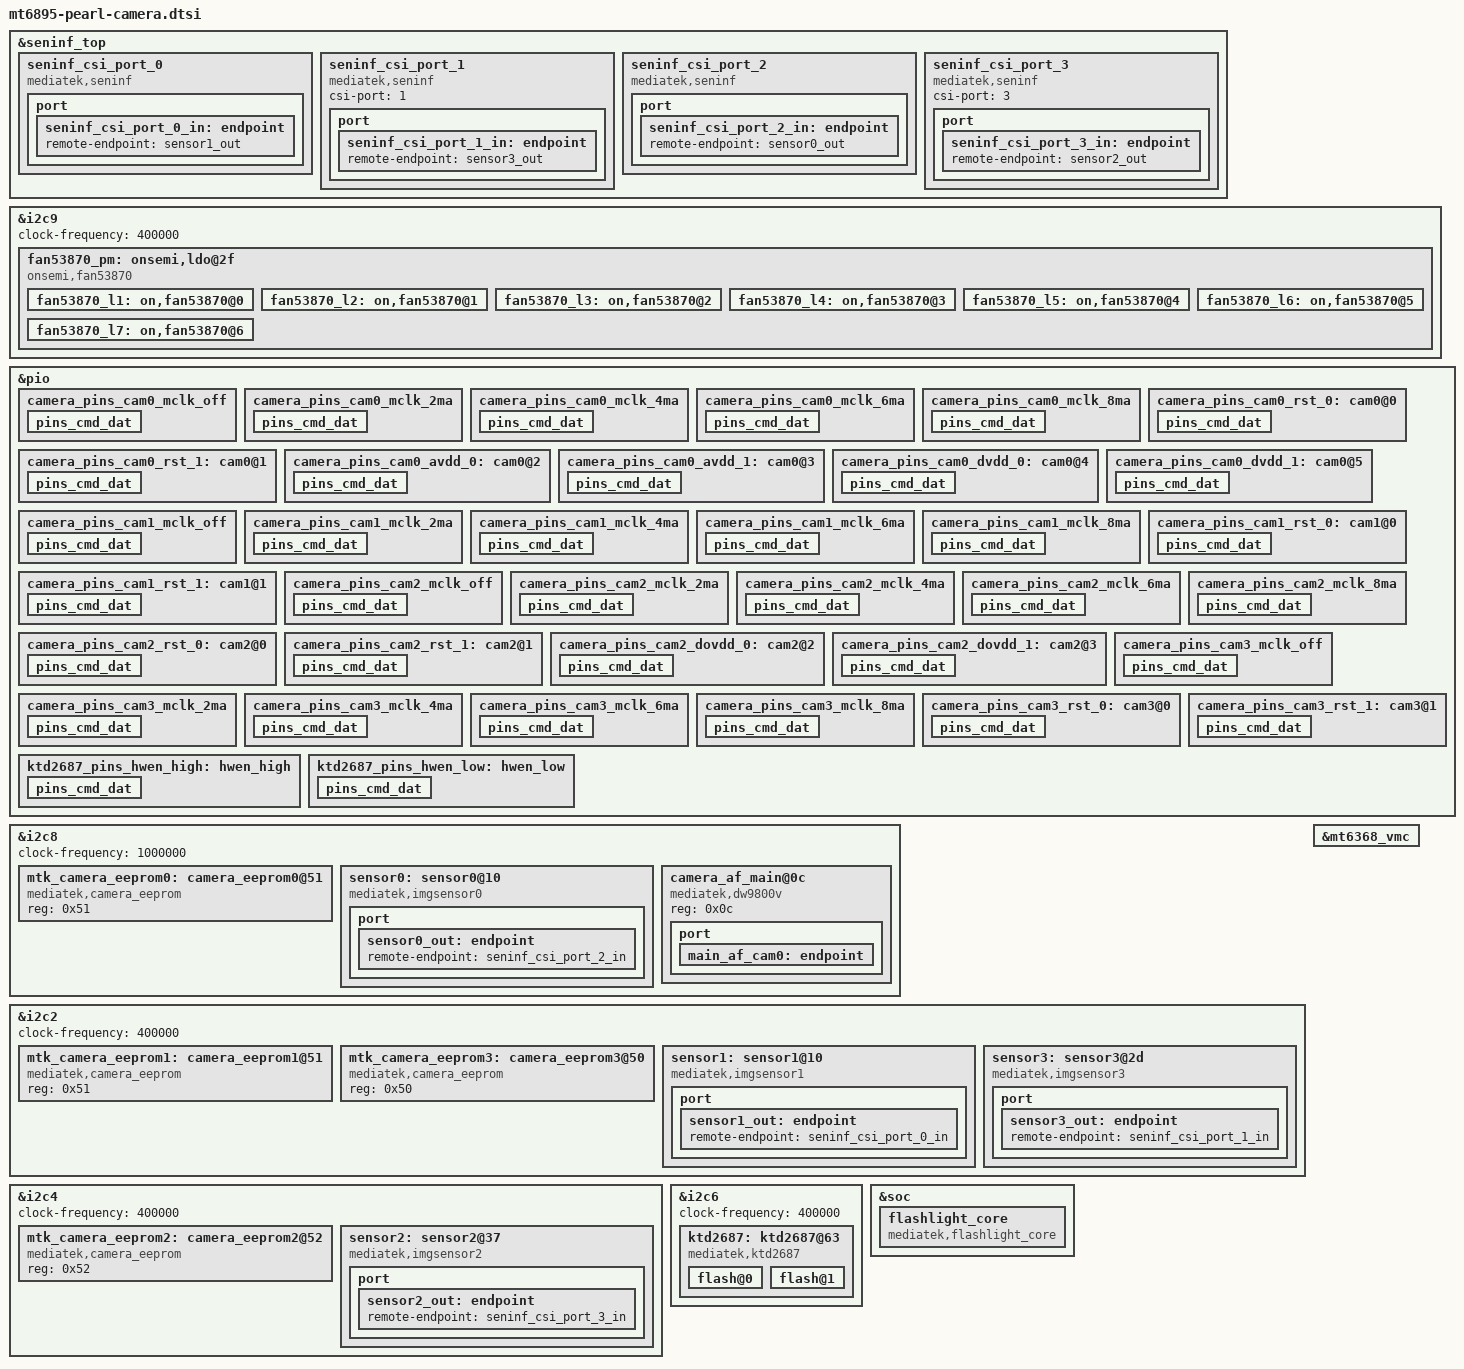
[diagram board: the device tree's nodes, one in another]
// SPDX-License-Identifier: GPL-2.0
/*
 * Copyright (c) 2020 MediaTek Inc.
 *
 * pearl (Redmi Note 12T Pro / MT6895) camera device tree.
 *
 * Every value here was taken from two independent sources and cross-checked
 * against each other:
 *
 *   1. the vendor kernel tree's pearl_mt6895_camera_v4l2.dtsi, and
 *   2. the stock firmware actually flashed on this device -- the dtbo
 *      partition (/dev/disk/by-partlabel/dtbo_a) was dumped, its embedded
 *      DTB extracted and decompiled, and the sensor nodes read out of it.
 *
 * They agree, which also settles the sensor question: pearl is NOT xaga.
 * xaga's main camera is an S5KGW1/S5KHM2; pearl's is an OV64B, and there is
 * no OV64B driver anywhere in the xaga-derived tree -- pearl's four sensor
 * drivers were ported separately from the vendor tree.
 *
 *   sensor0  pearl ov64b_mipi_raw    i2c8 @0x10  CSI port 2  (main, 64MP)
 *   sensor1  pearl ov16a1_mipi_raw   i2c2 @0x10  CSI port 0  (front, 16MP)
 *   sensor2  pearl gc02m1_mipi_raw   i2c4 @0x37  CSI port 3  (macro, 2MP)
 *   sensor3  pearl s5k4h7_mipi_raw   i2c2 @0x2d  CSI port 1  (sub, 8MP)
 *
 * All four are powered by the FAN53870 PMIC on i2c9 @0x35.  The EEPROMs
 * (calibration data) sit at 0x50/0x51/0x52 on the same buses as their
 * sensors, and the main camera additionally switches its own avdd/dvdd
 * through GPIOs (149/159), the macro its dovdd (144).
 */

#include <dt-bindings/clock/mt6895-clk.h>
#include <dt-bindings/gpio/gpio.h>
/* PINMUX_* macros come from mt6895-pinfunc.h, pulled in by mt6895.dtsi. */

/* ------------------------------------------------------------------ */
/* CSI receivers: which physical port each sensor lands on             */
/* ------------------------------------------------------------------ */
&seninf_top {
	seninf_csi_port_0: seninf_csi_port_0 {
		compatible = "mediatek,seninf";
		csi-port = "0";
		seninf_dphy_settle_delay_dt = <7>;
		dphy_settle_delay_dt = <7>;
		settle_delay_ck = <7>;
		hs_trail_parameter = <102>;
		status = "okay";

		port {
			seninf_csi_port_0_in: endpoint {
				remote-endpoint = <&sensor1_out>;
			};
		};
	};

	seninf_csi_port_1: seninf_csi_port_1 {
		compatible = "mediatek,seninf";
		csi-port = "1";
		status = "okay";

		port {
			seninf_csi_port_1_in: endpoint {
				remote-endpoint = <&sensor3_out>;
			};
		};
	};

	seninf_csi_port_2: seninf_csi_port_2 {
		compatible = "mediatek,seninf";
		csi-port = "2";
		seninf_dphy_settle_delay_dt = <7>;
		dphy_settle_delay_dt = <7>;
		settle_delay_ck = <7>;
		hs_trail_parameter = <32>;
		status = "okay";

		port {
			seninf_csi_port_2_in: endpoint {
				remote-endpoint = <&sensor0_out>;
			};
		};
	};

	seninf_csi_port_3: seninf_csi_port_3 {
		compatible = "mediatek,seninf";
		csi-port = "3";
		status = "okay";

		port {
			seninf_csi_port_3_in: endpoint {
				remote-endpoint = <&sensor2_out>;
			};
		};
	};
};

/* ------------------------------------------------------------------ */
/* FAN53870 camera PMIC: all four sensors hang off these rails         */
/* ------------------------------------------------------------------ */
&i2c9 {
	status = "okay";
	#address-cells = <1>;
	#size-cells = <0>;
	clock-frequency = <400000>;

	/*
	 * PEARL: real slave address is 0x2f, not the 0x35 the stock DT names.
	 * Measured with i2cdetect/i2cget on the running kernel:
	 *
	 *     0x35  -> "Error: Read failed"          (nothing there)
	 *     0x2f  -> PID=0x82 RID=0x33 IOUT=0x00 ENABLE=0x58 LDO0=0x58
	 *              0x05..0x09 = 0xa2 x5 (LDO1..LDO5)
	 *
	 * which is exactly the FAN53870 register map the driver defines
	 * (fan53870.c: REG_PID/RID/IOUT/ENABLE/LDO0 at 0x00..0x04).  sc8551
	 * answers on the same bus at 0x66, so the controller is fine -- the
	 * address in the DT was simply wrong, and the probe deferred forever,
	 * which is what all four sensors were waiting on.
	 */
	fan53870_pm: onsemi,ldo@2f {
		compatible = "onsemi,fan53870";
		reg = <0x2f>;
		index = <0>;
		/*
		 * PEARL: the driver's own comment names this rail.  Without
		 * it devm_regulator_get_optional("vin") returns -ENODEV, the
		 * probe runs with the chip unpowered, the PID read fails with
		 * -ENXIO and it defers forever -- which is exactly what the
		 * four camera sensors were waiting on.
		 */
		vin-supply = <&mt6368_vio28>;
		status = "okay";

		fan53870_l1: on,fan53870@0 {
			offset = /bits/ 16 <0x0000>;
			regulator-name = "fan53870-l1";
			regulator-min-microvolt = <528000>;
			regulator-max-microvolt = <1504000>;
			min-dropout-voltage = <225000>;
			init-voltage = <1150000>;
			iout_ua = <650000>;
		};

		fan53870_l2: on,fan53870@1 {
			offset = /bits/ 16 <0x0001>;
			regulator-name = "fan53870-l2";
			regulator-min-microvolt = <528000>;
			regulator-max-microvolt = <1504000>;
			min-dropout-voltage = <225000>;
			init-voltage = <1200000>;
			iout_ua = <650000>;
		};

		fan53870_l3: on,fan53870@2 {
			offset = /bits/ 16 <0x0002>;
			regulator-name = "fan53870-l3";
			regulator-min-microvolt = <1504000>;
			regulator-max-microvolt = <3400000>;
			min-dropout-voltage = <200000>;
			init-voltage = <2900000>;
			iout_ua = <650000>;
		};

		fan53870_l4: on,fan53870@3 {
			offset = /bits/ 16 <0x0003>;
			regulator-name = "fan53870-l4";
			regulator-min-microvolt = <1504000>;
			regulator-max-microvolt = <3400000>;
			min-dropout-voltage = <200000>;
			init-voltage = <2800000>;
			iout_ua = <650000>;
		};

		fan53870_l5: on,fan53870@4 {
			offset = /bits/ 16 <0x0004>;
			regulator-name = "fan53870-l5";
			regulator-min-microvolt = <1504000>;
			regulator-max-microvolt = <3400000>;
			min-dropout-voltage = <300000>;
			init-voltage = <2800000>;
			iout_ua = <650000>;
		};

		fan53870_l6: on,fan53870@5 {
			offset = /bits/ 16 <0x0005>;
			regulator-name = "fan53870-l6";
			regulator-min-microvolt = <1504000>;
			regulator-max-microvolt = <3400000>;
			min-dropout-voltage = <300000>;
			init-voltage = <2800000>;
			iout_ua = <650000>;
		};

		fan53870_l7: on,fan53870@6 {
			offset = /bits/ 16 <0x0006>;
			regulator-name = "fan53870-l7";
			regulator-min-microvolt = <1504000>;
			regulator-max-microvolt = <3400000>;
			min-dropout-voltage = <300000>;
			init-voltage = <2800000>;
			iout_ua = <650000>;
		};
	};
};

/* ------------------------------------------------------------------ */
/* Camera pin control                                                  */
/*                                                                     */
/* MCLK: cam0 = GPIO152 (CMMCLK2), cam1 = GPIO150 (CMMCLK0),           */
/*       cam2 = GPIO151 (CMMCLK1), cam3 = GPIO162 (CMMCLK3)            */
/* RESET: cam0 = 155, cam1 = 153, cam2 = 154, cam3 = 156               */
/* Main camera also gates its own avdd (149) and dvdd (159);           */
/* the macro gates its dovdd (144).                                    */
/* ------------------------------------------------------------------ */
&pio {
	camera_pins_cam0_mclk_off: camera_pins_cam0_mclk_off {
		pins_cmd_dat {
			pinmux = <PINMUX_GPIO152__FUNC_GPIO152>;
			drive-strength = <1>;
		};
	};
	camera_pins_cam0_mclk_2ma: camera_pins_cam0_mclk_2ma {
		pins_cmd_dat {
			pinmux = <PINMUX_GPIO152__FUNC_CMMCLK2>;
			drive-strength = <0>;
		};
	};
	camera_pins_cam0_mclk_4ma: camera_pins_cam0_mclk_4ma {
		pins_cmd_dat {
			pinmux = <PINMUX_GPIO152__FUNC_CMMCLK2>;
			drive-strength = <1>;
		};
	};
	camera_pins_cam0_mclk_6ma: camera_pins_cam0_mclk_6ma {
		pins_cmd_dat {
			pinmux = <PINMUX_GPIO152__FUNC_CMMCLK2>;
			drive-strength = <2>;
		};
	};
	camera_pins_cam0_mclk_8ma: camera_pins_cam0_mclk_8ma {
		pins_cmd_dat {
			pinmux = <PINMUX_GPIO152__FUNC_CMMCLK2>;
			drive-strength = <3>;
		};
	};
	camera_pins_cam0_rst_0: cam0@0 {
		pins_cmd_dat {
			pinmux = <PINMUX_GPIO155__FUNC_GPIO155>;
			slew-rate = <1>;
			output-low;
		};
	};
	camera_pins_cam0_rst_1: cam0@1 {
		pins_cmd_dat {
			pinmux = <PINMUX_GPIO155__FUNC_GPIO155>;
			slew-rate = <1>;
			output-high;
		};
	};
	camera_pins_cam0_avdd_0: cam0@2 {
		pins_cmd_dat {
			pinmux = <PINMUX_GPIO149__FUNC_GPIO149>;
			slew-rate = <1>;
			output-low;
		};
	};
	camera_pins_cam0_avdd_1: cam0@3 {
		pins_cmd_dat {
			pinmux = <PINMUX_GPIO149__FUNC_GPIO149>;
			slew-rate = <1>;
			output-high;
		};
	};
	camera_pins_cam0_dvdd_0: cam0@4 {
		pins_cmd_dat {
			pinmux = <PINMUX_GPIO159__FUNC_GPIO159>;
			slew-rate = <1>;
			output-low;
		};
	};
	camera_pins_cam0_dvdd_1: cam0@5 {
		pins_cmd_dat {
			pinmux = <PINMUX_GPIO159__FUNC_GPIO159>;
			slew-rate = <1>;
			output-high;
		};
	};

	camera_pins_cam1_mclk_off: camera_pins_cam1_mclk_off {
		pins_cmd_dat {
			pinmux = <PINMUX_GPIO150__FUNC_GPIO150>;
			drive-strength = <1>;
		};
	};
	camera_pins_cam1_mclk_2ma: camera_pins_cam1_mclk_2ma {
		pins_cmd_dat {
			pinmux = <PINMUX_GPIO150__FUNC_CMMCLK0>;
			drive-strength = <0>;
		};
	};
	camera_pins_cam1_mclk_4ma: camera_pins_cam1_mclk_4ma {
		pins_cmd_dat {
			pinmux = <PINMUX_GPIO150__FUNC_CMMCLK0>;
			drive-strength = <1>;
		};
	};
	camera_pins_cam1_mclk_6ma: camera_pins_cam1_mclk_6ma {
		pins_cmd_dat {
			pinmux = <PINMUX_GPIO150__FUNC_CMMCLK0>;
			drive-strength = <2>;
		};
	};
	camera_pins_cam1_mclk_8ma: camera_pins_cam1_mclk_8ma {
		pins_cmd_dat {
			pinmux = <PINMUX_GPIO150__FUNC_CMMCLK0>;
			drive-strength = <3>;
		};
	};
	camera_pins_cam1_rst_0: cam1@0 {
		pins_cmd_dat {
			pinmux = <PINMUX_GPIO153__FUNC_GPIO153>;
			slew-rate = <1>;
			output-low;
		};
	};
	camera_pins_cam1_rst_1: cam1@1 {
		pins_cmd_dat {
			pinmux = <PINMUX_GPIO153__FUNC_GPIO153>;
			slew-rate = <1>;
			output-high;
		};
	};

	camera_pins_cam2_mclk_off: camera_pins_cam2_mclk_off {
		pins_cmd_dat {
			pinmux = <PINMUX_GPIO151__FUNC_GPIO151>;
			drive-strength = <1>;
		};
	};
	camera_pins_cam2_mclk_2ma: camera_pins_cam2_mclk_2ma {
		pins_cmd_dat {
			pinmux = <PINMUX_GPIO151__FUNC_CMMCLK1>;
			drive-strength = <0>;
		};
	};
	camera_pins_cam2_mclk_4ma: camera_pins_cam2_mclk_4ma {
		pins_cmd_dat {
			pinmux = <PINMUX_GPIO151__FUNC_CMMCLK1>;
			drive-strength = <1>;
		};
	};
	camera_pins_cam2_mclk_6ma: camera_pins_cam2_mclk_6ma {
		pins_cmd_dat {
			pinmux = <PINMUX_GPIO151__FUNC_CMMCLK1>;
			drive-strength = <2>;
		};
	};
	camera_pins_cam2_mclk_8ma: camera_pins_cam2_mclk_8ma {
		pins_cmd_dat {
			pinmux = <PINMUX_GPIO151__FUNC_CMMCLK1>;
			drive-strength = <3>;
		};
	};
	camera_pins_cam2_rst_0: cam2@0 {
		pins_cmd_dat {
			pinmux = <PINMUX_GPIO154__FUNC_GPIO154>;
			slew-rate = <1>;
			output-low;
		};
	};
	camera_pins_cam2_rst_1: cam2@1 {
		pins_cmd_dat {
			pinmux = <PINMUX_GPIO154__FUNC_GPIO154>;
			slew-rate = <1>;
			output-high;
		};
	};
	camera_pins_cam2_dovdd_0: cam2@2 {
		pins_cmd_dat {
			pinmux = <PINMUX_GPIO144__FUNC_GPIO144>;
			slew-rate = <1>;
			output-low;
		};
	};
	camera_pins_cam2_dovdd_1: cam2@3 {
		pins_cmd_dat {
			pinmux = <PINMUX_GPIO144__FUNC_GPIO144>;
			slew-rate = <1>;
			output-high;
		};
	};

	camera_pins_cam3_mclk_off: camera_pins_cam3_mclk_off {
		pins_cmd_dat {
			pinmux = <PINMUX_GPIO162__FUNC_GPIO162>;
			drive-strength = <1>;
		};
	};
	camera_pins_cam3_mclk_2ma: camera_pins_cam3_mclk_2ma {
		pins_cmd_dat {
			pinmux = <PINMUX_GPIO162__FUNC_CMMCLK3>;
			drive-strength = <0>;
		};
	};
	camera_pins_cam3_mclk_4ma: camera_pins_cam3_mclk_4ma {
		pins_cmd_dat {
			pinmux = <PINMUX_GPIO162__FUNC_CMMCLK3>;
			drive-strength = <1>;
		};
	};
	camera_pins_cam3_mclk_6ma: camera_pins_cam3_mclk_6ma {
		pins_cmd_dat {
			pinmux = <PINMUX_GPIO162__FUNC_CMMCLK3>;
			drive-strength = <2>;
		};
	};
	camera_pins_cam3_mclk_8ma: camera_pins_cam3_mclk_8ma {
		pins_cmd_dat {
			pinmux = <PINMUX_GPIO162__FUNC_CMMCLK3>;
			drive-strength = <3>;
		};
	};
	camera_pins_cam3_rst_0: cam3@0 {
		pins_cmd_dat {
			pinmux = <PINMUX_GPIO156__FUNC_GPIO156>;
			slew-rate = <1>;
			output-low;
		};
	};
	camera_pins_cam3_rst_1: cam3@1 {
		pins_cmd_dat {
			pinmux = <PINMUX_GPIO156__FUNC_GPIO156>;
			slew-rate = <1>;
			output-high;
		};
	};
};

/* ------------------------------------------------------------------ */
/* sensor0: main camera, OV64B 64MP, on i2c8                           */
/* ------------------------------------------------------------------ */
&i2c8 {
	status = "okay";
	#address-cells = <1>;
	#size-cells = <0>;
	clock-frequency = <400000>;

	mtk_camera_eeprom0: camera_eeprom0@51 {
		compatible = "mediatek,camera_eeprom";
		reg = <0x51>;
		status = "okay";
	};

	sensor0: sensor0@10 {
		compatible = "mediatek,imgsensor0";
		reg = <0x10>;
		sensor-names = "pearlov64b_mipi_raw";
		#thermal-sensor-cells = <0>;

		pinctrl-names = "mclk_off",
				"mclk_2mA",
				"mclk_4mA",
				"mclk_6mA",
				"mclk_8mA",
				"rst_low",
				"rst_high",
				"avdd_off",
				"avdd_on",
				"dvdd_off",
				"dvdd_on";
		pinctrl-0 = <&camera_pins_cam0_mclk_off>;
		pinctrl-1 = <&camera_pins_cam0_mclk_2ma>;
		pinctrl-2 = <&camera_pins_cam0_mclk_4ma>;
		pinctrl-3 = <&camera_pins_cam0_mclk_6ma>;
		pinctrl-4 = <&camera_pins_cam0_mclk_8ma>;
		pinctrl-5 = <&camera_pins_cam0_rst_0>;
		pinctrl-6 = <&camera_pins_cam0_rst_1>;
		pinctrl-7 = <&camera_pins_cam0_avdd_0>;
		pinctrl-8 = <&camera_pins_cam0_avdd_1>;
		pinctrl-9 = <&camera_pins_cam0_dvdd_0>;
		pinctrl-10 = <&camera_pins_cam0_dvdd_1>;

		dovdd-supply = <&fan53870_l7>;
		afvdd-supply = <&fan53870_l6>;

		clocks = <&topckgen CLK_TOP_UNIVPLL_192M_D32>,
			<&topckgen CLK_TOP_UNIVPLL_192M_D16>,
			<&topckgen CLK_TOP_F26M_CK_D2>,
			<&topckgen CLK_TOP_UNIVPLL_192M_D10>,
			<&topckgen CLK_TOP_UNIVPLL_192M_D8>,
			<&clk26m>,
			<&topckgen CLK_TOP_UNIVPLL_D6_D8>,
			<&topckgen CLK_TOP_CAMTG_SEL>;
		clock-names = "6", "12", "13", "19.2", "24", "26", "52", "mclk";

		status = "okay";

		port {
			sensor0_out: endpoint {
				remote-endpoint = <&seninf_csi_port_2_in>;
			};
		};
	};
};

/* ------------------------------------------------------------------ */
/* sensor1 (front, OV16A1) and sensor3 (sub, S5K4H7) share i2c2        */
/* ------------------------------------------------------------------ */
&i2c2 {
	status = "okay";
	#address-cells = <1>;
	#size-cells = <0>;
	clock-frequency = <400000>;

	mtk_camera_eeprom1: camera_eeprom1@51 {
		compatible = "mediatek,camera_eeprom";
		reg = <0x51>;
		status = "okay";
	};

	mtk_camera_eeprom3: camera_eeprom3@50 {
		compatible = "mediatek,camera_eeprom";
		reg = <0x50>;
		status = "okay";
	};

	sensor1: sensor1@10 {
		compatible = "mediatek,imgsensor1";
		reg = <0x10>;
		sensor-names = "pearlov16a1_mipi_raw";
		#thermal-sensor-cells = <0>;

		pinctrl-names = "mclk_off",
				"mclk_2mA",
				"mclk_4mA",
				"mclk_6mA",
				"mclk_8mA",
				"rst_low",
				"rst_high";
		pinctrl-0 = <&camera_pins_cam1_mclk_off>;
		pinctrl-1 = <&camera_pins_cam1_mclk_2ma>;
		pinctrl-2 = <&camera_pins_cam1_mclk_4ma>;
		pinctrl-3 = <&camera_pins_cam1_mclk_6ma>;
		pinctrl-4 = <&camera_pins_cam1_mclk_8ma>;
		pinctrl-5 = <&camera_pins_cam1_rst_0>;
		pinctrl-6 = <&camera_pins_cam1_rst_1>;

		dovdd-supply = <&fan53870_l7>;
		avdd-supply = <&fan53870_l3>;
		dvdd-supply = <&fan53870_l1>;

		clocks = <&topckgen CLK_TOP_UNIVPLL_192M_D32>,
			<&topckgen CLK_TOP_UNIVPLL_192M_D16>,
			<&topckgen CLK_TOP_F26M_CK_D2>,
			<&topckgen CLK_TOP_UNIVPLL_192M_D10>,
			<&topckgen CLK_TOP_UNIVPLL_192M_D8>,
			<&clk26m>,
			<&topckgen CLK_TOP_UNIVPLL_D6_D8>,
			<&topckgen CLK_TOP_CAMTG_SEL>;
		clock-names = "6", "12", "13", "19.2", "24", "26", "52", "mclk";

		status = "okay";

		port {
			sensor1_out: endpoint {
				remote-endpoint = <&seninf_csi_port_0_in>;
			};
		};
	};

	sensor3: sensor3@2d {
		compatible = "mediatek,imgsensor3";
		reg = <0x2d>;
		sensor-names = "pearls5k4h7_mipi_raw";
		#thermal-sensor-cells = <0>;

		pinctrl-names = "mclk_off",
				"mclk_2mA",
				"mclk_4mA",
				"mclk_6mA",
				"mclk_8mA",
				"rst_low",
				"rst_high";
		pinctrl-0 = <&camera_pins_cam3_mclk_off>;
		pinctrl-1 = <&camera_pins_cam3_mclk_2ma>;
		pinctrl-2 = <&camera_pins_cam3_mclk_4ma>;
		pinctrl-3 = <&camera_pins_cam3_mclk_6ma>;
		pinctrl-4 = <&camera_pins_cam3_mclk_8ma>;
		pinctrl-5 = <&camera_pins_cam3_rst_0>;
		pinctrl-6 = <&camera_pins_cam3_rst_1>;

		dovdd-supply = <&fan53870_l7>;
		avdd-supply = <&fan53870_l4>;
		dvdd-supply = <&fan53870_l2>;

		clocks = <&topckgen CLK_TOP_UNIVPLL_192M_D32>,
			<&topckgen CLK_TOP_UNIVPLL_192M_D16>,
			<&topckgen CLK_TOP_F26M_CK_D2>,
			<&topckgen CLK_TOP_UNIVPLL_192M_D10>,
			<&topckgen CLK_TOP_UNIVPLL_192M_D8>,
			<&clk26m>,
			<&topckgen CLK_TOP_UNIVPLL_D6_D8>,
			<&topckgen CLK_TOP_CAMTG_SEL>;
		clock-names = "6", "12", "13", "19.2", "24", "26", "52", "mclk";

		status = "okay";

		port {
			sensor3_out: endpoint {
				remote-endpoint = <&seninf_csi_port_1_in>;
			};
		};
	};
};

/* ------------------------------------------------------------------ */
/* sensor2: macro camera, GC02M1 2MP, on i2c4                          */
/* ------------------------------------------------------------------ */
&i2c4 {
	status = "okay";
	#address-cells = <1>;
	#size-cells = <0>;
	clock-frequency = <400000>;

	mtk_camera_eeprom2: camera_eeprom2@52 {
		compatible = "mediatek,camera_eeprom";
		reg = <0x52>;
		status = "okay";
	};

	sensor2: sensor2@37 {
		compatible = "mediatek,imgsensor2";
		reg = <0x37>;
		sensor-names = "pearlgc02m1_mipi_raw";
		#thermal-sensor-cells = <0>;

		pinctrl-names = "mclk_off",
				"mclk_2mA",
				"mclk_4mA",
				"mclk_6mA",
				"mclk_8mA",
				"rst_low",
				"rst_high",
				"dovdd_off",
				"dovdd_on";
		pinctrl-0 = <&camera_pins_cam2_mclk_off>;
		pinctrl-1 = <&camera_pins_cam2_mclk_2ma>;
		pinctrl-2 = <&camera_pins_cam2_mclk_4ma>;
		pinctrl-3 = <&camera_pins_cam2_mclk_6ma>;
		pinctrl-4 = <&camera_pins_cam2_mclk_8ma>;
		pinctrl-5 = <&camera_pins_cam2_rst_0>;
		pinctrl-6 = <&camera_pins_cam2_rst_1>;
		pinctrl-7 = <&camera_pins_cam2_dovdd_0>;
		pinctrl-8 = <&camera_pins_cam2_dovdd_1>;

		avdd-supply = <&fan53870_l5>;

		clocks = <&topckgen CLK_TOP_UNIVPLL_192M_D32>,
			<&topckgen CLK_TOP_UNIVPLL_192M_D16>,
			<&topckgen CLK_TOP_F26M_CK_D2>,
			<&topckgen CLK_TOP_UNIVPLL_192M_D10>,
			<&topckgen CLK_TOP_UNIVPLL_192M_D8>,
			<&clk26m>,
			<&topckgen CLK_TOP_UNIVPLL_D6_D8>,
			<&topckgen CLK_TOP_CAMTG_SEL>;
		clock-names = "6", "12", "13", "19.2", "24", "26", "52", "mclk";

		status = "okay";

		port {
			sensor2_out: endpoint {
				remote-endpoint = <&seninf_csi_port_3_in>;
			};
		};
	};
};

/*
 * PEARL: FAN53870 VIN.  The stock pearl DT overrides this rail in
 * pearl-mt6895.dtsi:
 *
 *     &mt6368_vmc {
 *             regulator-min-microvolt = <3300000>;
 *             regulator-max-microvolt = <3300000>;
 *             regulator-always-on;
 *     };
 *
 * Without it the rail stays off (measured: "mt6368_vmc: disabled
 * 1800000uV"), the camera PMIC at i2c9/0x35 never answers -- while sc8551
 * on the same bus probes fine, so the bus itself is healthy -- and its
 * probe defers forever.  All four sensors wait on regulators from that
 * chip, which is why none of them ever bound.
 */
&mt6368_vmc {
	regulator-min-microvolt = <3300000>;
	regulator-max-microvolt = <3300000>;
	regulator-always-on;
};


/* ------------------------------------------------------------------ */
/* PEARL: AF (DW9800V) and flashlight (KTD2687)                        */
/*                                                                     */
/* Ported from the vendor tree:                                        */
/*   drivers/misc/mediatek/lens/vcm/v4l2/dw9800v/                      */
/*   drivers/misc/mediatek/flashlight/v4l2/ktd2687.c                   */
/* The vendor's pearl_mt6895_camera_v4l2.dtsi puts the AF on i2c8 at   */
/* 0x0c and the flash on i2c6 at 0x63 (with GPIO119 as the hardware    */
/* enable).  The media port links are intentionally left out for now   */
/* -- first make sure both chips probe, then wire them into the graph. */
/* ------------------------------------------------------------------ */

&i2c8 {
	status = "okay";
	#address-cells = <1>;
	#size-cells = <0>;
	clock-frequency = <1000000>;

	camera_af_main@0c {
		compatible = "mediatek,dw9800v";
		reg = <0x0c>;
		status = "okay";

		port {
			main_af_cam0: endpoint {
			};
		};
	};
};

&i2c6 {
	status = "okay";
	#address-cells = <1>;
	#size-cells = <0>;
	clock-frequency = <400000>;

	ktd2687: ktd2687@63 {
		compatible = "mediatek,ktd2687";
		reg = <0x63>;
		/*
		 * PEARL: "default" makes the pinctrl core raise HWEN at probe
		 * time, so the chip is powered before the driver touches it.
		 * Without it the driver only raises HWEN inside its own init
		 * path, and the pin is left low after a power-off.
		 */
		pinctrl-names = "default", "hwen_high", "hwen_low";
		pinctrl-0 = <&ktd2687_pins_hwen_high>;
		pinctrl-1 = <&ktd2687_pins_hwen_high>;
		pinctrl-2 = <&ktd2687_pins_hwen_low>;
		status = "okay";

		flash@0 {
			reg = <0>;
			type = <0>;
			ct = <0>;
			part = <0>;
		};

		flash@1 {
			reg = <1>;
			type = <0>;
			ct = <1>;
			part = <0>;
		};
	};
};

&pio {
	ktd2687_pins_hwen_high: hwen_high {
		pins_cmd_dat {
			pinmux = <PINMUX_GPIO119__FUNC_GPIO119>;
			slew-rate = <1>;
			output-high;
		};
	};

	ktd2687_pins_hwen_low: hwen_low {
		pins_cmd_dat {
			pinmux = <PINMUX_GPIO119__FUNC_GPIO119>;
			slew-rate = <1>;
			output-low;
		};
	};
};


/* ------------------------------------------------------------------ */
/* PEARL: flashlight framework platform device                         */
/*                                                                     */
/* flashlight-core.c matches "mediatek,flashlight_core"                */
/* (flashlight-core.c:3142); its probe creates /dev/flashlight and the */
/* /sys/class/flashlight_core/ attribute group.  Vendor boards put the */
/* node inside soc (mt6853.dtsi:4652, mt6873.dtsi:4942).               */
/* ------------------------------------------------------------------ */
&soc {
	flashlight_core: flashlight_core {
		compatible = "mediatek,flashlight_core";
	};
};
